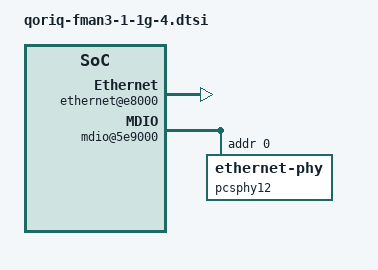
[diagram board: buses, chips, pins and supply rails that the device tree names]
// SPDX-License-Identifier: (GPL-2.0+ OR BSD-3-Clause)
/*
 * QorIQ FMan v3 1g port #4 device tree stub [ controller @ offset 0x500000 ]
 *
 * Copyright 2012 - 2015 Freescale Semiconductor Inc.
 * Copyright 2020 NXP
 *
 */

fman@500000 {
	fman1_rx_0x0c: port@8c000 {
		cell-index = <0xc>;
		compatible = "fsl,fman-v3-port-rx";
		reg = <0x8c000 0x1000>;
	};

	fman1_tx_0x2c: port@ac000 {
		cell-index = <0x2c>;
		compatible = "fsl,fman-v3-port-tx";
		reg = <0xac000 0x1000>;
	};

	ethernet@e8000 {
		cell-index = <4>;
		compatible = "fsl,fman-memac";
		reg = <0xe8000 0x1000>;
		fsl,fman-ports = <&fman1_rx_0x0c &fman1_tx_0x2c>;
		ptp-timer = <&ptp_timer1>;
		pcsphy-handle = <&pcsphy12>;
	};

	mdio@5e9000 {
		#address-cells = <1>;
		#size-cells = <0>;
		compatible = "fsl,fman-memac-mdio", "fsl,fman-xmdio";
		reg = <0xe9000 0x1000>;
		fsl,erratum-a011043; /* must ignore read errors */

		pcsphy12: ethernet-phy@0 {
			reg = <0x0>;
		};
	};
};
